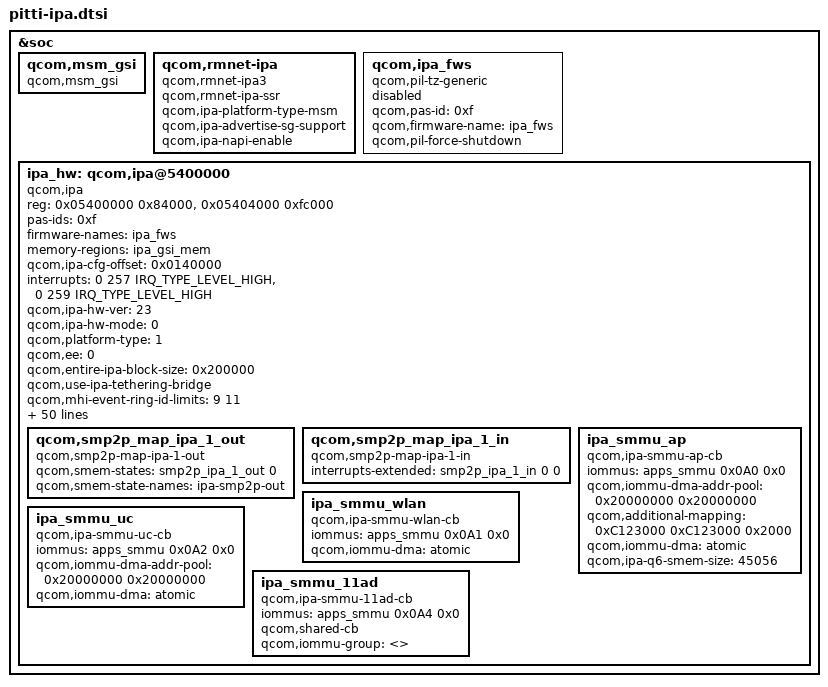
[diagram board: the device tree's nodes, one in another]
&soc {
        qcom,msm_gsi {
                compatible = "qcom,msm_gsi";
        };

        qcom,rmnet-ipa {
                compatible = "qcom,rmnet-ipa3";
                qcom,rmnet-ipa-ssr;
                qcom,ipa-platform-type-msm;
                qcom,ipa-advertise-sg-support;
                qcom,ipa-napi-enable;
        };

        qcom,ipa_fws {
                compatible = "qcom,pil-tz-generic";
                qcom,pas-id = <0xf>;
                qcom,firmware-name = "ipa_fws";
                qcom,pil-force-shutdown;
                status = "disabled";
        };

        ipa_hw: qcom,ipa@5400000 {
                compatible = "qcom,ipa";
                reg =
                        <0x05400000 0x84000>,
                        <0x05404000 0xfc000>;
                reg-names = "ipa-base", "gsi-base";
                pas-ids = <0xf>;
                firmware-names = "ipa_fws";
                memory-regions = <&ipa_gsi_mem>;
                qcom,ipa-cfg-offset = <0x0140000>;
                interrupts =
                        <0 257 IRQ_TYPE_LEVEL_HIGH>,
                        <0 259 IRQ_TYPE_LEVEL_HIGH>;
                interrupt-names = "ipa-irq", "gsi-irq";
                qcom,ipa-hw-ver = <23>; /* IPA core version = IPAv5.2 */
                qcom,ipa-hw-mode = <0>;
                qcom,platform-type = <1>; /* MSM platform */
                qcom,ee = <0>;
                qcom,entire-ipa-block-size = <0x200000>;
                qcom,use-ipa-tethering-bridge;
                qcom,mhi-event-ring-id-limits = <9 11>; /* start and end */
                qcom,modem-cfg-emb-pipe-flt;
                qcom,ipa-wdi3-over-gsi;
                qcom,arm-smmu;
                qcom,smmu-fast-map;
                qcom,use-64-bit-dma-mask;
                qcom,ipa-endp-delay-wa-v2;
                qcom,lan-rx-napi;
                qcom,tx-napi;
                qcom,tx-poll;
                qcom,register-collection-on-crash;
                qcom,testbus-collection-on-crash;
                qcom,non-tn-collection-on-crash;
                qcom,wan-use-skb-page;
                qcom,rmnet-ctl-enable;
                qcom,ipa-uc-holb-monitor;
                qcom,ipa-holb-monitor-poll-period = <5>;
                qcom,ipa-holb-monitor-max-cnt-wlan = <10>;
                qcom,ipa-holb-monitor-max-cnt-usb = <10>;
                qcom,ipa-holb-monitor-max-cnt-11ad = <10>;
                qcom,tx-wrapper-cache-max-size = <400>;
                qcom,ipa-gpi-event-rp-ddr;
                qcom,ulso-supported;
                qcom,ulso-ip-id-min-linux-val = <0>;
                qcom,ulso-ip-id-max-linux-val = <0xffff>;
                qcom,ulso-ip-id-min-windows-val = <0>;
                qcom,ulso-ip-id-max-windows-val = <0x7fff>;
                qcom,wan-rx-ring-size = <128>;
                qcom,ipa-gen-rx-cmn-page-pool-sz-factor = <3>;
                qcom,ipa-gen-rx-cmn-temp-pool-sz-factor = <2>;
                qcom,max_num_smmu_cb = <4>;
                clock-names = "core_clk";
                clocks = <&rpmcc RPM_SMD_IPA_CLK>;
                qcom,interconnect,num-cases = <5>;
                qcom,interconnect,num-paths = <3>;
                interconnects = <&system_noc MASTER_IPA &bimc SLAVE_EBI_CH0>,
                                <&system_noc MASTER_IPA &system_noc SLAVE_OCIMEM>,
                                <&bimc MASTER_AMPSS_M0 &config_noc SLAVE_IPA_CFG>;
                interconnect-names = "ipa_to_ebi1", "ipa_to_imem", "appss_to_ipa";

                /* No vote */
                qcom,no-vote =
                <0 0 0 0 0 0>;

                /* SVS2 */
                qcom,svs2 =
                <80000 465000 80000 68570 80000 30>;

                /* SVS */
                qcom,svs =
                <80000 2000000 80000 267461 80000 109890>;

                /* NOMINAL */
                qcom,nominal =
                <206000 4000000 206000 712961 206000 491520>;

                /* TURBO */
                qcom,turbo =
                <206000 5598900 206000 1436481 206000 491520>;

                qcom,bus-vector-names = "MIN", "SVS2", "SVS", "NOMINAL",
                        "TURBO";

                qcom,throughput-threshold = <600 2500 5000>;
                qcom,scaling-exceptions = <>;

                /* smp2p information */
                qcom,smp2p_map_ipa_1_out {
                        compatible = "qcom,smp2p-map-ipa-1-out";
                        qcom,smem-states = <&smp2p_ipa_1_out 0>;
                        qcom,smem-state-names = "ipa-smp2p-out";
                };

                qcom,smp2p_map_ipa_1_in {
                        compatible = "qcom,smp2p-map-ipa-1-in";
                        interrupts-extended = <&smp2p_ipa_1_in 0 0>;
                        interrupt-names = "ipa-smp2p-in";
                };

                ipa_smmu_ap: ipa_smmu_ap {
                        compatible = "qcom,ipa-smmu-ap-cb";
                        iommus = <&apps_smmu 0x0A0 0x0>;
                        qcom,iommu-dma-addr-pool = <0x20000000 0x20000000>;
                        qcom,additional-mapping =
                                /* modem tables in IMEM */
                                <0xC123000 0xC123000 0x2000>;
                        qcom,iommu-dma = "atomic";
                        qcom,ipa-q6-smem-size = <45056>;
                };

                ipa_smmu_wlan: ipa_smmu_wlan {
                        compatible = "qcom,ipa-smmu-wlan-cb";
                        iommus = <&apps_smmu 0x0A1 0x0>;
                        qcom,iommu-dma = "atomic";
                };

                ipa_smmu_uc: ipa_smmu_uc {
                        compatible = "qcom,ipa-smmu-uc-cb";
                        iommus = <&apps_smmu 0x0A2 0x0>;
                        qcom,iommu-dma-addr-pool = <0x20000000 0x20000000>;
                        qcom,iommu-dma = "atomic";
                };

                ipa_smmu_11ad: ipa_smmu_11ad {
                        compatible = "qcom,ipa-smmu-11ad-cb";
                        iommus = <&apps_smmu 0x0A4 0x0>;
                        qcom,shared-cb;
                        qcom,iommu-group = <>;
                };
        };
};
